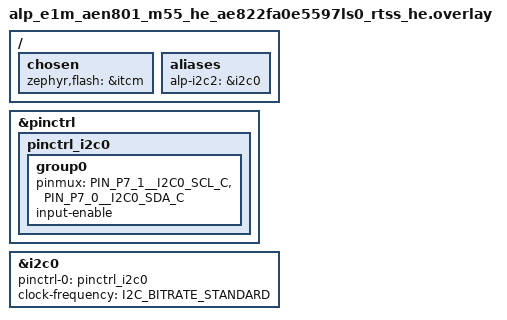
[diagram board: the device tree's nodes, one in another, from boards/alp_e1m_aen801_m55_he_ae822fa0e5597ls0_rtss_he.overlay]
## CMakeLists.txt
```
# SPDX-License-Identifier: Apache-2.0

cmake_minimum_required(VERSION 3.20)

find_package(Zephyr REQUIRED HINTS $ENV{ZEPHYR_BASE})
project(aen_secure_element_sign LANGUAGES C)

target_sources(app PRIVATE src/main.c)
```

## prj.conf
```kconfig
# SPDX-License-Identifier: Apache-2.0
#
# Feature CONFIG_* are derived from board.yaml by `tan build`
# and layered in via EXTRA_CONF_FILE (see scripts/gen_example_alp_conf.py).  Only the
# console/logging knobs the example itself needs live here.
CONFIG_PRINTK=y

# The board.yaml-derived alp.conf enables CONFIG_LOG globally; keep printk
# direct so RAM-console bench runs do not depend on the deferred logger path.
CONFIG_LOG_PRINTK=n
```

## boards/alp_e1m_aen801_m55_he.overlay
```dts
/*
 * Copyright (c) 2026 Alp Lab AB
 * SPDX-License-Identifier: Apache-2.0
 *
 * aen-secure-element-sign overlay for the E1M-AEN801 (Ensemble E8,
 * M55-HE) RAM-run.  Retarget ROM to ITCM so Flow C can load and run
 * this image without writing MRAM.
 */

/ {
	chosen {
		zephyr,flash = &itcm;
		/delete-property/ zephyr,code-partition;
	};
};
```

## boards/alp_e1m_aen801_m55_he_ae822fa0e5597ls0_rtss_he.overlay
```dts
/*
 * Copyright (c) 2026 Alp Lab AB
 * SPDX-License-Identifier: Apache-2.0
 *
 * aen-secure-element-sign overlay for the E1M-AEN801 (Ensemble E8,
 * M55-HE) RAM-run.  Retarget ROM to ITCM so Flow C can load and run
 * this image without writing MRAM, and wire BRD_I2C (#1848).
 */

#include <zephyr/dt-bindings/pinctrl/alif-ensemble-pinctrl.h>
#include <zephyr/dt-bindings/i2c/i2c.h>

/ {
	chosen {
		zephyr,flash = &itcm;
		/delete-property/ zephyr,code-partition;
	};
};

/*
 * BRD_I2C (SoC I2C0, function C) -- on-module housekeeping bus: RV-3028-C7
 * RTC (0x52), OPTIGA Trust M secure element (0x30), TMP112 temperature
 * sensor (0x48).  I2C0_SCL_C = P7_1, I2C0_SDA_C = P7_0 (ADTS0013 v1.2 Table
 * 3-16); corroborated by the E1M-AEN-2626-R2 netlist (BRD_I2C_SCL/SDA on
 * balls B3/B8).  R2-SOURCED, NOT ON-UNIT-VERIFIED -- the bench module on
 * hand is r1 and no R1 netlist is available (#1848).
 *
 * NO internal pull (deliberately -- do not add bias-pull-down): the R2
 * components CSV shows the BRD_I2C pull-up jumpers (R93/R94) DNP -- this
 * net has NO external pull-up, unlike the I2C2/EEPROM bus this pinctrl
 * shape was otherwise copied from (whose pull-up jumpers R95/R96 ARE
 * stuffed, feeding carrier resistors R137/R144 to +VIO).  A pull-DOWN here
 * would park both lines low through the pad's ~50 kOhm Rpd and make the
 * bus look permanently busy.  There is also an unresolved document
 * conflict this bench needs to settle before adding any bias: the
 * datasheet's per-pin table marks I2C0_SCL_C/I2C0_SDA_C "open-drain output
 * driver, requires external pull-up", while the HWRM's per-pin note for
 * these ports says I2C "is operating properly with the push-pull (default)
 * driver type" and that open-drain "must not be selected for I2C". If the
 * IP tri-states for the high phase, no pull-up means a dead bus; if it
 * drives push-pull, the missing pull-up is by design either way. High-Z
 * (no bias-pull-*) is the safe default until a bench probe (scope on
 * P7_0/P7_1, or a controlled bias-pull-up trial) resolves which reading is
 * right -- see the ADR 0017 amendment.
 *
 * P7_0/P7_1 carry no E1M edge route, so this pad claim lives only in prose
 * (here + the dtsi + the ADR amendment) -- `check_pin_conflicts.py` reads
 * `metadata/e1m_modules/aen/*.tsv` only and does not see it; its PASS is not
 * evidence this pair is exclusively claimed.
 */
&pinctrl {
	pinctrl_i2c0: pinctrl_i2c0 {
		group0 {
			pinmux = <PIN_P7_1__I2C0_SCL_C>, <PIN_P7_0__I2C0_SDA_C>;
			input-enable;
		};
	};
};

&i2c0 {
	status = "okay";
	pinctrl-0 = <&pinctrl_i2c0>;
	pinctrl-names = "default";
	/* 100 kHz: no fast-mode margin without a confirmed pull-up (see above). */
	clock-frequency = <I2C_BITRATE_STANDARD>;
};

/ {
	aliases {
		/* Bus index 2: 0 and 1 are already the E1M edge buses
		 * (ALP_E1M_I2C0 / ALP_E1M_I2C1, e.g. BOARD_I2C_SENSORS /
		 * EVK_I2C_BUS_DSI_CSI) -- BRD_I2C has no E1M route of its own,
		 * so it takes the next free portable index instead of one
		 * already claimed by an edge bus (#1848). */
		alp-i2c2 = &i2c0;
	};
};
```

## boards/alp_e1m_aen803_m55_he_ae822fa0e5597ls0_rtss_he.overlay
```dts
/*
 * Copyright (c) 2026 Alp Lab AB
 * SPDX-License-Identifier: Apache-2.0
 *
 * aen-secure-element-sign overlay for the E1M-AEN803 (Ensemble E8,
 * M55-HE) RAM-run.  Retarget ROM to ITCM so Flow C can load and run
 * this image without writing MRAM, and wire BRD_I2C (#1848).
 */

#include <zephyr/dt-bindings/pinctrl/alif-ensemble-pinctrl.h>
#include <zephyr/dt-bindings/i2c/i2c.h>

/ {
	chosen {
		zephyr,flash = &itcm;
		/delete-property/ zephyr,code-partition;
	};
};

/*
 * BRD_I2C (SoC I2C0, function C) -- on-module housekeeping bus: RV-3028-C7
 * RTC (0x52), OPTIGA Trust M secure element (0x30), TMP112 temperature
 * sensor (0x48).  I2C0_SCL_C = P7_1, I2C0_SDA_C = P7_0 (ADTS0013 v1.2 Table
 * 3-16); corroborated by the E1M-AEN-2626-R2 netlist (BRD_I2C_SCL/SDA on
 * balls B3/B8).  R2-SOURCED, NOT ON-UNIT-VERIFIED -- the bench module on
 * hand is r1 and no R1 netlist is available (#1848).
 *
 * NO internal pull (deliberately -- do not add bias-pull-down): the R2
 * components CSV shows the BRD_I2C pull-up jumpers (R93/R94) DNP -- this
 * net has NO external pull-up, unlike the I2C2/EEPROM bus this pinctrl
 * shape was otherwise copied from (whose pull-up jumpers R95/R96 ARE
 * stuffed, feeding carrier resistors R137/R144 to +VIO).  A pull-DOWN here
 * would park both lines low through the pad's ~50 kOhm Rpd and make the
 * bus look permanently busy.  There is also an unresolved document
 * conflict this bench needs to settle before adding any bias: the
 * datasheet's per-pin table marks I2C0_SCL_C/I2C0_SDA_C "open-drain output
 * driver, requires external pull-up", while the HWRM's per-pin note for
 * these ports says I2C "is operating properly with the push-pull (default)
 * driver type" and that open-drain "must not be selected for I2C". If the
 * IP tri-states for the high phase, no pull-up means a dead bus; if it
 * drives push-pull, the missing pull-up is by design either way. High-Z
 * (no bias-pull-*) is the safe default until a bench probe (scope on
 * P7_0/P7_1, or a controlled bias-pull-up trial) resolves which reading is
 * right -- see the ADR 0017 amendment.
 *
 * P7_0/P7_1 carry no E1M edge route, so this pad claim lives only in prose
 * (here + the dtsi + the ADR amendment) -- `check_pin_conflicts.py` reads
 * `metadata/e1m_modules/aen/*.tsv` only and does not see it; its PASS is not
 * evidence this pair is exclusively claimed.
 */
&pinctrl {
	pinctrl_i2c0: pinctrl_i2c0 {
		group0 {
			pinmux = <PIN_P7_1__I2C0_SCL_C>, <PIN_P7_0__I2C0_SDA_C>;
			input-enable;
		};
	};
};

&i2c0 {
	status = "okay";
	pinctrl-0 = <&pinctrl_i2c0>;
	pinctrl-names = "default";
	/* 100 kHz: no fast-mode margin without a confirmed pull-up (see above). */
	clock-frequency = <I2C_BITRATE_STANDARD>;
};

/ {
	aliases {
		/* Bus index 2: 0 and 1 are already the E1M edge buses
		 * (ALP_E1M_I2C0 / ALP_E1M_I2C1, e.g. BOARD_I2C_SENSORS /
		 * EVK_I2C_BUS_DSI_CSI) -- BRD_I2C has no E1M route of its own,
		 * so it takes the next free portable index instead of one
		 * already claimed by an edge bus (#1848). */
		alp-i2c2 = &i2c0;
	};
};
```

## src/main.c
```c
/*
 * Copyright 2026 Alp Lab AB
 * SPDX-License-Identifier: Apache-2.0
 *
 * aen-secure-element-sign -- talk to the OPTIGA Trust M on the E1M-AEN
 * (Alif Ensemble) SoM.
 *
 * On the E1M-AEN the Trust M sits on **BRD_I2C** -- the on-module
 * housekeeping bus (SoC I2C0, function C, P7_1 SCL / P7_0 SDA --
 * CORRECTED #1848, earlier revisions of this file believed it was the
 * slave-only Alif LPI2C0) -- at 7-bit address 0x30, alongside the RTC +
 * TMP112.
 * (A different, separate bus carries the EEPROM -- SoC I2C2, see
 * docs/bring-up-aen.md §5.1.)  This example's board target is rtss_he
 * (M55-HE); this example's own overlay wires BRD_I2C (portable bus 2 --
 * 0 and 1 are already the E1M edge I2C buses).  The chip and the sign
 * flow are identical to the V2N variant -- everything goes through the
 * SoM-portable <alp/...> API, so the only AEN-specific facts are the
 * bus + the owning core.
 *
 * The BRD_I2C routing above is R2-sourced (E1M-AEN-2626-R2 netlist +
 * ADTS0013); no R1 netlist is available, and the bench unit on hand is
 * r1, so it still needs an on-unit probe.  It is also open-drain with NO
 * confirmed external pull-up (see the board overlay's pinctrl comment) --
 * do not add bias-pull-down.
 *
 * The driver probes I2C_STATE, then reads the Coprocessor UID through
 * Infineon's host library.  examples/v2n/v2n-secure-element-sign also
 * runs a raw APDU session; it is the bench-verified variant (E1M-V2M103).
 * Nothing here writes to the chip.
 */

#include <zephyr/kernel.h>

#include "alp/peripheral.h"
#include "alp/chips/optiga_trust_m.h"

int main(void)
{
	printk("[se] aen-secure-element-sign (probe-only)\n");

	/* BRD_I2C carries the Trust M alongside the RTC + TMP112 (the
     * EEPROM is on a separate bus, SoC I2C2 -- see docs/bring-up-aen.md
     * §5.1).  On the E1M-AEN this is SoC I2C0 (#1848), surfaced as
     * portable bus 2 by this example's own board overlay (0 and 1 are
     * already the E1M edge I2C buses).  100 kHz, matching the board DT:
     * BRD_I2C has no confirmed external pull-up, so there is no fast-mode
     * margin here -- do not raise this past standard-mode. */
	alp_i2c_t *bus = alp_i2c_open(&(alp_i2c_config_t){
	    .bus_id     = 2u,
	    .bitrate_hz = 100000u,
	});
	if (bus == NULL) {
		/* NOT_READY vs anything else matters here: NOT_READY means "the BRD_I2C
		 * backend isn't wired up on this build/board" -- an environment gap,
		 * not a driver bug -- so it's a SKIP. Any other code means the open
		 * itself is broken and should fail the run. */
		const alp_status_t last = alp_last_error();
		if (last == ALP_ERR_NOT_READY) {
			printk("[se] RESULT SKIP: alp_i2c_open failed: %d "
			       "(BRD_I2C not ready on this bench)\n",
			       (int)last);
		} else {
			printk("[se] RESULT FAIL: alp_i2c_open failed: %d\n", (int)last);
		}
		printk("[se] done\n");
		return 0;
	}

	/* Init probes I2C_STATE only -- it does not issue OPEN_APPLICATION, so it
	 * never touches the Trust M's application/security state. This makes the
	 * probe safe to run against a part that's already provisioned in the
	 * field: it can only observe that something ACKs at 0x30. */
	optiga_trust_m_t se;
	alp_status_t     s = optiga_trust_m_init(&se, bus, OPTIGA_TRUST_M_I2C_ADDR);
	if (s != ALP_OK) {
		/* Same SKIP/FAIL split as above, one level down: NOT_READY here means
		 * the bus opened but nothing ACKed at 0x30 -- expected on the current
		 * AEN bench batch, which is OPTIGA-DNI (not populated), not a defect. */
		if (s == ALP_ERR_NOT_READY) {
			printk("[se] RESULT SKIP: optiga_trust_m_init -> %d "
			       "(Trust M not ACKing; current AEN bench assemblies may be OPTIGA-DNI)\n",
			       (int)s);
		} else {
			printk("[se] RESULT FAIL: optiga_trust_m_init -> %d\n", (int)s);
		}
		alp_i2c_close(bus);
		printk("[se] done\n");
		return 0;
	}

	printk("[se] I2C_STATE probe -> ALP_OK\n");

	/* Coprocessor UID (data object 0xE0C2): opens the Trust M application
	 * through the host library and reads it.  Read-only. */
	optiga_trust_m_product_info_t info;
	s = optiga_trust_m_read_product_info(&se, &info);
	if (s != ALP_OK) {
		printk("[se] RESULT FAIL: read_product_info -> %d\n", (int)s);
		optiga_trust_m_deinit(&se);
		alp_i2c_close(bus);
		printk("[se] done\n");
		return 0;
	}
	printk("[se] UID: cim %02X platform %02X model %02X fw %02X%02X%02X%02X build %02X%02X\n",
	       info.cim_id,
	       info.platform_id,
	       info.model_id,
	       info.fw_id[0],
	       info.fw_id[1],
	       info.fw_id[2],
	       info.fw_id[3],
	       info.esw_build[0],
	       info.esw_build[1]);

	optiga_trust_m_deinit(&se);
	alp_i2c_close(bus);
	printk("[se] RESULT PASS: Trust M probe and Coprocessor UID read work\n");
	printk("[se] done\n");
	return 0;
}
```
